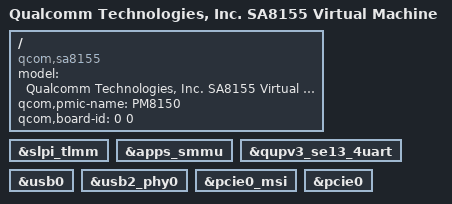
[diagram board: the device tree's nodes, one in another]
// SPDX-License-Identifier: GPL-2.0
/*
 * Copyright (c) 2018-2019, The Linux Foundation. All rights reserved.
 */

/dts-v1/;

#include "sa8155-vm.dtsi"

/ {
	model = "Qualcomm Technologies, Inc. SA8155 Virtual Machine";
	compatible = "qcom,sa8155";
	qcom,pmic-name = "PM8150";
	qcom,board-id = <0 0>;
};

&slpi_tlmm {
	status = "ok";
};

&apps_smmu {
	status = "ok";
};

&qupv3_se13_4uart {
	status = "ok";
};

&usb0 {
	status = "ok";
};

&usb2_phy0 {
	status = "ok";
};

&pcie0_msi {
	status = "ok";
};

&pcie0 {
	status = "ok";
};
